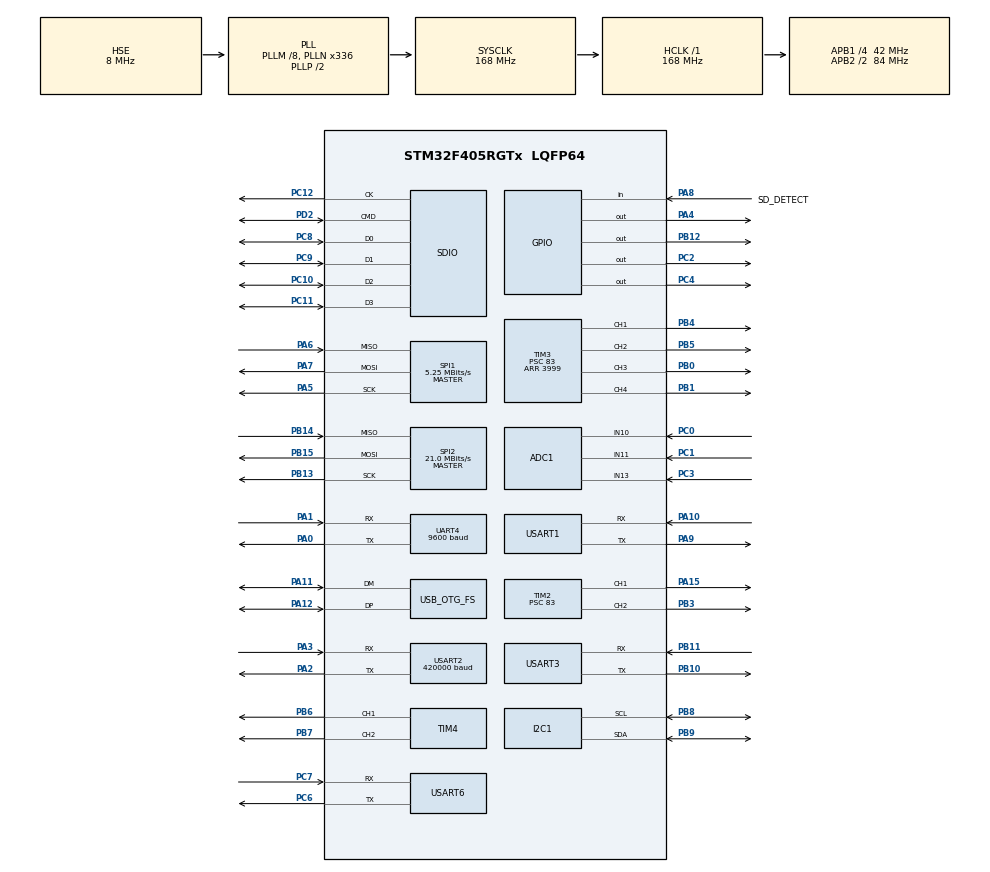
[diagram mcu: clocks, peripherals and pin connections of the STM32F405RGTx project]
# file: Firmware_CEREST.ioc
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ADC1.Channel-0\#ChannelRegularConversion=ADC_CHANNEL_10
ADC1.NbrOfConversionFlag=1
ADC1.Rank-0\#ChannelRegularConversion=1
ADC1.SamplingTime-0\#ChannelRegularConversion=ADC_SAMPLETIME_3CYCLES
ADC1.master=1
Dma.Request0=UART4_TX
Dma.Request1=USART2_RX
Dma.Request2=USART2_TX
Dma.Request3=USART6_RX
Dma.Request4=USART6_TX
Dma.UART4_TX.0.Direction=DMA_MEMORY_TO_PERIPH
Dma.UART4_TX.0.FIFOMode=DMA_FIFOMODE_DISABLE
Dma.UART4_TX.0.Instance=DMA1_Stream4
Dma.UART4_TX.0.MemDataAlignment=DMA_MDATAALIGN_BYTE
Dma.UART4_TX.0.MemInc=DMA_MINC_ENABLE
Dma.UART4_TX.0.Mode=DMA_NORMAL
Dma.UART4_TX.0.PeriphDataAlignment=DMA_PDATAALIGN_BYTE
Dma.UART4_TX.0.PeriphInc=DMA_PINC_DISABLE
Dma.UART4_TX.0.Priority=DMA_PRIORITY_LOW
Dma.USART2_RX.1.Direction=DMA_PERIPH_TO_MEMORY
Dma.USART2_RX.1.FIFOMode=DMA_FIFOMODE_DISABLE
Dma.USART2_RX.1.Instance=DMA1_Stream5
Dma.USART2_RX.1.MemDataAlignment=DMA_MDATAALIGN_BYTE
Dma.USART2_RX.1.MemInc=DMA_MINC_ENABLE
Dma.USART2_RX.1.Mode=DMA_CIRCULAR
Dma.USART2_RX.1.PeriphDataAlignment=DMA_PDATAALIGN_BYTE
Dma.USART2_RX.1.PeriphInc=DMA_PINC_DISABLE
Dma.USART2_RX.1.Priority=DMA_PRIORITY_VERY_HIGH
Dma.USART2_TX.2.Direction=DMA_MEMORY_TO_PERIPH
Dma.USART2_TX.2.FIFOMode=DMA_FIFOMODE_DISABLE
Dma.USART2_TX.2.Instance=DMA1_Stream6
Dma.USART2_TX.2.MemDataAlignment=DMA_MDATAALIGN_BYTE
Dma.USART2_TX.2.MemInc=DMA_MINC_ENABLE
Dma.USART2_TX.2.Mode=DMA_NORMAL
Dma.USART2_TX.2.PeriphDataAlignment=DMA_PDATAALIGN_BYTE
Dma.USART2_TX.2.PeriphInc=DMA_PINC_DISABLE
Dma.USART2_TX.2.Priority=DMA_PRIORITY_VERY_HIGH
Dma.USART6_RX.3.Direction=DMA_PERIPH_TO_MEMORY
Dma.USART6_RX.3.FIFOMode=DMA_FIFOMODE_DISABLE
Dma.USART6_RX.3.Instance=DMA2_Stream1
Dma.USART6_RX.3.MemDataAlignment=DMA_MDATAALIGN_BYTE
Dma.USART6_RX.3.MemInc=DMA_MINC_ENABLE
Dma.USART6_RX.3.Mode=DMA_CIRCULAR
Dma.USART6_RX.3.PeriphDataAlignment=DMA_PDATAALIGN_BYTE
Dma.USART6_RX.3.PeriphInc=DMA_PINC_DISABLE
Dma.USART6_RX.3.Priority=DMA_PRIORITY_VERY_HIGH
Dma.USART6_TX.4.Direction=DMA_MEMORY_TO_PERIPH
Dma.USART6_TX.4.FIFOMode=DMA_FIFOMODE_DISABLE
Dma.USART6_TX.4.Instance=DMA2_Stream6
Dma.USART6_TX.4.MemDataAlignment=DMA_MDATAALIGN_BYTE
Dma.USART6_TX.4.MemInc=DMA_MINC_ENABLE
Dma.USART6_TX.4.Mode=DMA_NORMAL
Dma.USART6_TX.4.PeriphDataAlignment=DMA_PDATAALIGN_BYTE
Dma.USART6_TX.4.PeriphInc=DMA_PINC_DISABLE
Dma.USART6_TX.4.Priority=DMA_PRIORITY_VERY_HIGH
FATFS._MAX_SS=4096
I2C1.I2C_Mode=I2C_Fast
Mcu.Family=STM32F4
Mcu.Name=STM32F405RGTx
Mcu.Package=LQFP64
NVIC.DMA1_Stream4_IRQn=true\:0\:0\:false\:false\:true\:false\:true\:true
NVIC.DMA1_Stream5_IRQn=true\:0\:0\:false\:false\:true\:false\:true\:true
NVIC.DMA1_Stream6_IRQn=true\:0\:0\:false\:false\:true\:false\:true\:true
NVIC.DMA2_Stream1_IRQn=true\:0\:0\:false\:false\:true\:false\:true\:true
NVIC.DMA2_Stream6_IRQn=true\:0\:0\:false\:false\:true\:false\:true\:true
NVIC.OTG_FS_IRQn=true\:0\:0\:false\:false\:true\:false\:true\:true
NVIC.PriorityGroup=NVIC_PRIORITYGROUP_4
NVIC.SDIO_IRQn=true\:0\:0\:false\:false\:true\:true\:true\:true
NVIC.UART4_IRQn=true\:0\:0\:false\:false\:true\:true\:true\:true
NVIC.USART2_IRQn=true\:0\:0\:false\:false\:true\:true\:true\:true
NVIC.USART6_IRQn=true\:0\:0\:false\:false\:true\:true\:true\:true
PA0-WKUP.Mode=Asynchronous
PA0-WKUP.Signal=UART4_TX
PA1.Mode=Asynchronous
PA1.Signal=UART4_RX
PA10.Mode=Asynchronous
PA10.Signal=USART1_RX
PA11.Mode=Device_Only
PA11.Signal=USB_OTG_FS_DM
PA12.Mode=Device_Only
PA12.Signal=USB_OTG_FS_DP
PA13.Mode=Serial_Wire
PA13.Signal=SYS_JTMS-SWDIO
PA14.Mode=Serial_Wire
PA14.Signal=SYS_JTCK-SWCLK
PA15.Signal=S_TIM2_CH1_ETR
PA2.Mode=Asynchronous
PA2.Signal=USART2_TX
PA3.Mode=Asynchronous
PA3.Signal=USART2_RX
PA4.Signal=GPIO_Output
PA5.Mode=Full_Duplex_Master
PA5.Signal=SPI1_SCK
PA6.Mode=Full_Duplex_Master
PA6.Signal=SPI1_MISO
PA7.Mode=Full_Duplex_Master
PA7.Signal=SPI1_MOSI
PA8.GPIO_Label=SD_DETECT
PA8.GPIO_PuPd=GPIO_PULLUP
PA8.Signal=GPIO_Input
PA9.Mode=Asynchronous
PA9.Signal=USART1_TX
PB0.Signal=S_TIM3_CH3
PB1.Signal=S_TIM3_CH4
PB10.Mode=Asynchronous
PB10.Signal=USART3_TX
PB11.Mode=Asynchronous
PB11.Signal=USART3_RX
PB12.Signal=GPIO_Output
PB13.Mode=Full_Duplex_Master
PB13.Signal=SPI2_SCK
PB14.Mode=Full_Duplex_Master
PB14.Signal=SPI2_MISO
PB15.Mode=Full_Duplex_Master
PB15.Signal=SPI2_MOSI
PB3.Signal=S_TIM2_CH2
PB4.Signal=S_TIM3_CH1
PB5.Signal=S_TIM3_CH2
PB6.Signal=S_TIM4_CH1
PB7.Signal=S_TIM4_CH2
PB8.Mode=I2C
PB8.Signal=I2C1_SCL
PB9.Mode=I2C
PB9.Signal=I2C1_SDA
PC0.Signal=ADCx_IN10
PC1.Signal=ADCx_IN11
PC10.GPIO_PuPd=GPIO_PULLUP
PC10.Mode=SD_4_bits_Wide_bus
PC10.Signal=SDIO_D2
PC11.GPIO_PuPd=GPIO_PULLUP
PC11.Mode=SD_4_bits_Wide_bus
PC11.Signal=SDIO_D3
PC12.Mode=SD_4_bits_Wide_bus
PC12.Signal=SDIO_CK
PC2.GPIO_PuPd=GPIO_NOPULL
PC2.PinState=GPIO_PIN_SET
PC2.Signal=GPIO_Output
PC3.Signal=ADCx_IN13
PC4.GPIO_PuPd=GPIO_NOPULL
PC4.PinState=GPIO_PIN_RESET
PC4.Signal=GPIO_Output
PC6.Mode=Asynchronous
PC6.Signal=USART6_TX
PC7.Mode=Asynchronous
PC7.Signal=USART6_RX
PC8.GPIO_PuPd=GPIO_PULLUP
PC8.Mode=SD_4_bits_Wide_bus
PC8.Signal=SDIO_D0
PC9.GPIO_PuPd=GPIO_PULLUP
PC9.Mode=SD_4_bits_Wide_bus
PC9.Signal=SDIO_D1
PD2.GPIO_PuPd=GPIO_PULLUP
PD2.Mode=SD_4_bits_Wide_bus
PD2.Signal=SDIO_CMD
PH0-OSC_IN.Mode=HSE-External-Oscillator
PH0-OSC_IN.Signal=RCC_OSC_IN
PH1-OSC_OUT.Mode=HSE-External-Oscillator
PH1-OSC_OUT.Signal=RCC_OSC_OUT
ProjectManager.HeapSize=0x200
ProjectManager.StackSize=0x400
ProjectManager.TargetToolchain=CMake
RCC.48MHZClocksFreq_Value=48000000
RCC.AHBFreq_Value=168000000
RCC.APB1CLKDivider=RCC_HCLK_DIV4
RCC.APB1Freq_Value=42000000
RCC.APB1TimFreq_Value=84000000
RCC.APB2CLKDivider=RCC_HCLK_DIV2
RCC.APB2Freq_Value=84000000
RCC.APB2TimFreq_Value=168000000
RCC.CortexFreq_Value=168000000
RCC.HCLKFreq_Value=168000000
RCC.HSE_VALUE=8000000
RCC.HSI_VALUE=16000000
RCC.LSE_VALUE=32768
RCC.PLLM=8
RCC.PLLN=336
RCC.PLLQ=7
RCC.SYSCLKFreq_VALUE=168000000
RCC.SYSCLKSource=RCC_SYSCLKSOURCE_PLLCLK
RCC.VCOOutputFreq_Value=336000000
SDIO.ClockDiv=8
SH.ADCx_IN10.0=ADC1_IN10,IN10
SH.ADCx_IN11.0=ADC1_IN11,IN11
SH.ADCx_IN13.0=ADC1_IN13,IN13
SH.S_TIM2_CH1_ETR.0=TIM2_CH1,PWM Generation1 CH1
SH.S_TIM2_CH2.0=TIM2_CH2,PWM Generation2 CH2
SH.S_TIM3_CH1.0=TIM3_CH1,PWM Generation1 CH1
SH.S_TIM3_CH2.0=TIM3_CH2,PWM Generation2 CH2
SH.S_TIM3_CH3.0=TIM3_CH3,PWM Generation3 CH3
SH.S_TIM3_CH4.0=TIM3_CH4,PWM Generation4 CH4
SH.S_TIM4_CH1.0=TIM4_CH1,PWM Generation1 CH1
SH.S_TIM4_CH2.0=TIM4_CH2,PWM Generation2 CH2
SPI1.BaudRatePrescaler=SPI_BAUDRATEPRESCALER_16
SPI1.CalculateBaudRate=5.25 MBits/s
SPI1.Direction=SPI_DIRECTION_2LINES
SPI1.Mode=SPI_MODE_MASTER
SPI1.VirtualType=VM_MASTER
SPI2.BaudRatePrescaler=SPI_BAUDRATEPRESCALER_2
SPI2.CalculateBaudRate=21.0 MBits/s
SPI2.Direction=SPI_DIRECTION_2LINES
SPI2.Mode=SPI_MODE_MASTER
SPI2.VirtualType=VM_MASTER
TIM2.Channel-PWM\ Generation1\ CH1=TIM_CHANNEL_1
TIM2.Channel-PWM\ Generation2\ CH2=TIM_CHANNEL_2
TIM2.Period=19999
TIM2.Prescaler=83
TIM3.Channel-PWM\ Generation1\ CH1=TIM_CHANNEL_1
TIM3.Channel-PWM\ Generation2\ CH2=TIM_CHANNEL_2
TIM3.Channel-PWM\ Generation3\ CH3=TIM_CHANNEL_3
TIM3.Channel-PWM\ Generation4\ CH4=TIM_CHANNEL_4
TIM3.OC1Preload_PWM=ENABLE
TIM3.OC2Preload_PWM=ENABLE
TIM3.OCMode_PWM-PWM\ Generation1\ CH1=TIM_OCMODE_PWM1
TIM3.OCMode_PWM-PWM\ Generation2\ CH2=TIM_OCMODE_PWM1
TIM3.OCPolarity_1=TIM_OCPOLARITY_HIGH
TIM3.OCPolarity_2=TIM_OCPOLARITY_HIGH
TIM3.Period=3999
TIM3.Prescaler=83
TIM4.Channel-PWM\ Generation1\ CH1=TIM_CHANNEL_1
TIM4.Channel-PWM\ Generation2\ CH2=TIM_CHANNEL_2
TIM5.Prescaler=83
UART4.BaudRate=9600
UART4.VirtualMode=Asynchronous
USART1.VirtualMode=VM_ASYNC
USART2.BaudRate=420000
USART2.VirtualMode=VM_ASYNC
USART3.VirtualMode=VM_ASYNC
USART6.VirtualMode=VM_ASYNC
USB_DEVICE.CLASS_NAME_FS=CDC
USB_DEVICE.VirtualMode-CDC_FS=Cdc
USB_DEVICE.VirtualModeFS=Cdc_FS
USB_OTG_FS.VirtualMode=Device_Only
VP_FATFS_VS_SDIO.Mode=SDIO
VP_TIM2_VS_ClockSourceINT.Mode=Internal
VP_TIM3_VS_ClockSourceINT.Mode=Internal
VP_TIM5_VS_ClockSourceINT.Mode=Internal
VP_USB_DEVICE_VS_USB_DEVICE_CDC_FS.Mode=CDC_FS
board=custom

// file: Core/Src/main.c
/* USER CODE BEGIN Header */
/**
  ******************************************************************************
  * @file           : main.c
  * @brief          : Main program body
  ******************************************************************************
  * @attention
  *
  * Copyright (c) 2026 STMicroelectronics.
  * All rights reserved.
  *
  * This software is licensed under terms that can be found in the LICENSE file
  * in the root directory of this software component.
  * If no LICENSE file comes with this software, it is provided AS-IS.
  *
  ******************************************************************************
  */
/* USER CODE END Header */
#include "main.h"
#include "fatfs.h"
#include "usb_device.h"

/* USER CODE BEGIN Includes */
#include "puente.h"
/* USER CODE END Includes */

ADC_HandleTypeDef hadc1;

I2C_HandleTypeDef hi2c1;

SD_HandleTypeDef hsd;

SPI_HandleTypeDef hspi1;
SPI_HandleTypeDef hspi2;

TIM_HandleTypeDef htim2;
TIM_HandleTypeDef htim3;
TIM_HandleTypeDef htim4;
TIM_HandleTypeDef htim5;

UART_HandleTypeDef huart4;
UART_HandleTypeDef huart1;
UART_HandleTypeDef huart2;
UART_HandleTypeDef huart3;
UART_HandleTypeDef huart6;
DMA_HandleTypeDef hdma_uart4_tx;
DMA_HandleTypeDef hdma_usart2_rx;
DMA_HandleTypeDef hdma_usart2_tx;
DMA_HandleTypeDef hdma_usart6_rx;
DMA_HandleTypeDef hdma_usart6_tx;

void SystemClock_Config(void);
static void MX_GPIO_Init(void);
static void MX_DMA_Init(void);
static void MX_SPI2_Init(void);
static void MX_I2C1_Init(void);
static void MX_UART4_Init(void);
static void MX_USART6_UART_Init(void);
static void MX_USART2_UART_Init(void);
static void MX_TIM3_Init(void);
static void MX_TIM4_Init(void);
static void MX_TIM2_Init(void);
static void MX_SPI1_Init(void);
static void MX_ADC1_Init(void);
static void MX_TIM5_Init(void);
static void MX_SDIO_SD_Init(void);
static void MX_USART1_UART_Init(void);
static void MX_USART3_UART_Init(void);

int main(void)
{

  /* MCU Configuration--------------------------------------------------------*/

  /* Reset of all peripherals, Initializes the Flash interface and the Systick. */
  HAL_Init();

  /* Configure the system clock */
  SystemClock_Config();

  /* Initialize all configured peripherals */
  MX_GPIO_Init();
  MX_DMA_Init();
  MX_SPI2_Init();
  MX_USB_DEVICE_Init();
  MX_I2C1_Init();
  MX_UART4_Init();
  MX_USART6_UART_Init();
  MX_USART2_UART_Init();
  MX_TIM3_Init();
  MX_TIM4_Init();
  MX_TIM2_Init();
  MX_SPI1_Init();
  MX_ADC1_Init();
  MX_TIM5_Init();
  MX_SDIO_SD_Init();
  MX_USART1_UART_Init();
  MX_USART3_UART_Init();
  MX_FATFS_Init();
  /* USER CODE BEGIN 2 */
  HAL_TIM_Base_Start(&htim5);
  App_Init();
  /* USER CODE END 2 */

  /* Infinite loop */
  while (1)
  {

    /* USER CODE BEGIN 3 */
    App_Loop();
  }
  /* USER CODE END 3 */
}

void SystemClock_Config(void)
{
  RCC_OscInitTypeDef RCC_OscInitStruct = {0};
  RCC_ClkInitTypeDef RCC_ClkInitStruct = {0};

  /** Configure the main internal regulator output voltage
  */
  __HAL_RCC_PWR_CLK_ENABLE();
  __HAL_PWR_VOLTAGESCALING_CONFIG(PWR_REGULATOR_VOLTAGE_SCALE1);

  /** Initializes the RCC Oscillators according to the specified parameters
  * in the RCC_OscInitTypeDef structure.
  */
  RCC_OscInitStruct.OscillatorType = RCC_OSCILLATORTYPE_HSE;
  RCC_OscInitStruct.HSEState = RCC_HSE_ON;
  RCC_OscInitStruct.PLL.PLLState = RCC_PLL_ON;
  RCC_OscInitStruct.PLL.PLLSource = RCC_PLLSOURCE_HSE;
  RCC_OscInitStruct.PLL.PLLM = 8;
  RCC_OscInitStruct.PLL.PLLN = 336;
  RCC_OscInitStruct.PLL.PLLP = RCC_PLLP_DIV2;
  RCC_OscInitStruct.PLL.PLLQ = 7;
  if (HAL_RCC_OscConfig(&RCC_OscInitStruct) != HAL_OK)
  {
    Error_Handler();
  }

  /** Initializes the CPU, AHB and APB buses clocks
  */
  RCC_ClkInitStruct.ClockType = RCC_CLOCKTYPE_HCLK|RCC_CLOCKTYPE_SYSCLK
                              |RCC_CLOCKTYPE_PCLK1|RCC_CLOCKTYPE_PCLK2;
  RCC_ClkInitStruct.SYSCLKSource = RCC_SYSCLKSOURCE_PLLCLK;
  RCC_ClkInitStruct.AHBCLKDivider = RCC_SYSCLK_DIV1;
  RCC_ClkInitStruct.APB1CLKDivider = RCC_HCLK_DIV4;
  RCC_ClkInitStruct.APB2CLKDivider = RCC_HCLK_DIV2;

  if (HAL_RCC_ClockConfig(&RCC_ClkInitStruct, FLASH_LATENCY_5) != HAL_OK)
  {
    Error_Handler();
  }
}

static void MX_ADC1_Init(void)
{

  ADC_ChannelConfTypeDef sConfig = {0};

  /** Configure the global features of the ADC (Clock, Resolution, Data Alignment and number of conversion)
  */
  hadc1.Instance = ADC1;
  hadc1.Init.ClockPrescaler = ADC_CLOCK_SYNC_PCLK_DIV4;
  hadc1.Init.Resolution = ADC_RESOLUTION_12B;
  hadc1.Init.ScanConvMode = DISABLE;
  hadc1.Init.ContinuousConvMode = DISABLE;
  hadc1.Init.DiscontinuousConvMode = DISABLE;
  hadc1.Init.ExternalTrigConvEdge = ADC_EXTERNALTRIGCONVEDGE_NONE;
  hadc1.Init.ExternalTrigConv = ADC_SOFTWARE_START;
  hadc1.Init.DataAlign = ADC_DATAALIGN_RIGHT;
  hadc1.Init.NbrOfConversion = 1;
  hadc1.Init.DMAContinuousRequests = DISABLE;
  hadc1.Init.EOCSelection = ADC_EOC_SINGLE_CONV;
  if (HAL_ADC_Init(&hadc1) != HAL_OK)
  {
    Error_Handler();
  }

  /** Configure for the selected ADC regular channel its corresponding rank in the sequencer and its sample time.
  */
  sConfig.Channel = ADC_CHANNEL_10;
  sConfig.Rank = 1;
  sConfig.SamplingTime = ADC_SAMPLETIME_3CYCLES;
  if (HAL_ADC_ConfigChannel(&hadc1, &sConfig) != HAL_OK)
  {
    Error_Handler();
  }

}

static void MX_I2C1_Init(void)
{

  hi2c1.Instance = I2C1;
  hi2c1.Init.ClockSpeed = 400000;
  hi2c1.Init.DutyCycle = I2C_DUTYCYCLE_2;
  hi2c1.Init.OwnAddress1 = 0;
  hi2c1.Init.AddressingMode = I2C_ADDRESSINGMODE_7BIT;
  hi2c1.Init.DualAddressMode = I2C_DUALADDRESS_DISABLE;
  hi2c1.Init.OwnAddress2 = 0;
  hi2c1.Init.GeneralCallMode = I2C_GENERALCALL_DISABLE;
  hi2c1.Init.NoStretchMode = I2C_NOSTRETCH_DISABLE;
  if (HAL_I2C_Init(&hi2c1) != HAL_OK)
  {
    Error_Handler();
  }

}

static void MX_SDIO_SD_Init(void)
{

  hsd.Instance = SDIO;
  hsd.Init.ClockEdge = SDIO_CLOCK_EDGE_RISING;
  hsd.Init.ClockBypass = SDIO_CLOCK_BYPASS_DISABLE;
  hsd.Init.ClockPowerSave = SDIO_CLOCK_POWER_SAVE_DISABLE;
  hsd.Init.BusWide = SDIO_BUS_WIDE_1B;
  hsd.Init.HardwareFlowControl = SDIO_HARDWARE_FLOW_CONTROL_DISABLE;
  hsd.Init.ClockDiv = 8;

}

static void MX_SPI1_Init(void)
{

  /* SPI1 parameter configuration*/
  hspi1.Instance = SPI1;
  hspi1.Init.Mode = SPI_MODE_MASTER;
  hspi1.Init.Direction = SPI_DIRECTION_2LINES;
  hspi1.Init.DataSize = SPI_DATASIZE_8BIT;
  hspi1.Init.CLKPolarity = SPI_POLARITY_LOW;
  hspi1.Init.CLKPhase = SPI_PHASE_1EDGE;
  hspi1.Init.NSS = SPI_NSS_SOFT;
  hspi1.Init.BaudRatePrescaler = SPI_BAUDRATEPRESCALER_16;
  hspi1.Init.FirstBit = SPI_FIRSTBIT_MSB;
  hspi1.Init.TIMode = SPI_TIMODE_DISABLE;
  hspi1.Init.CRCCalculation = SPI_CRCCALCULATION_DISABLE;
  hspi1.Init.CRCPolynomial = 10;
  if (HAL_SPI_Init(&hspi1) != HAL_OK)
  {
    Error_Handler();
  }

}

static void MX_SPI2_Init(void)
{

  /* SPI2 parameter configuration*/
  hspi2.Instance = SPI2;
  hspi2.Init.Mode = SPI_MODE_MASTER;
  hspi2.Init.Direction = SPI_DIRECTION_2LINES;
  hspi2.Init.DataSize = SPI_DATASIZE_8BIT;
  hspi2.Init.CLKPolarity = SPI_POLARITY_LOW;
  hspi2.Init.CLKPhase = SPI_PHASE_1EDGE;
  hspi2.Init.NSS = SPI_NSS_SOFT;
  hspi2.Init.BaudRatePrescaler = SPI_BAUDRATEPRESCALER_2;
  hspi2.Init.FirstBit = SPI_FIRSTBIT_MSB;
  hspi2.Init.TIMode = SPI_TIMODE_DISABLE;
  hspi2.Init.CRCCalculation = SPI_CRCCALCULATION_DISABLE;
  hspi2.Init.CRCPolynomial = 10;
  if (HAL_SPI_Init(&hspi2) != HAL_OK)
  {
    Error_Handler();
  }

}

static void MX_TIM2_Init(void)
{

  TIM_ClockConfigTypeDef sClockSourceConfig = {0};
  TIM_MasterConfigTypeDef sMasterConfig = {0};
  TIM_OC_InitTypeDef sConfigOC = {0};

  htim2.Instance = TIM2;
  htim2.Init.Prescaler = 83;
  htim2.Init.CounterMode = TIM_COUNTERMODE_UP;
  htim2.Init.Period = 19999;
  htim2.Init.ClockDivision = TIM_CLOCKDIVISION_DIV1;
  htim2.Init.AutoReloadPreload = TIM_AUTORELOAD_PRELOAD_DISABLE;
  if (HAL_TIM_Base_Init(&htim2) != HAL_OK)
  {
    Error_Handler();
  }
  sClockSourceConfig.ClockSource = TIM_CLOCKSOURCE_INTERNAL;
  if (HAL_TIM_ConfigClockSource(&htim2, &sClockSourceConfig) != HAL_OK)
  {
    Error_Handler();
  }
  if (HAL_TIM_PWM_Init(&htim2) != HAL_OK)
  {
    Error_Handler();
  }
  sMasterConfig.MasterOutputTrigger = TIM_TRGO_RESET;
  sMasterConfig.MasterSlaveMode = TIM_MASTERSLAVEMODE_DISABLE;
  if (HAL_TIMEx_MasterConfigSynchronization(&htim2, &sMasterConfig) != HAL_OK)
  {
    Error_Handler();
  }
  sConfigOC.OCMode = TIM_OCMODE_PWM1;
  sConfigOC.Pulse = 0;
  sConfigOC.OCPolarity = TIM_OCPOLARITY_HIGH;
  sConfigOC.OCFastMode = TIM_OCFAST_DISABLE;
  if (HAL_TIM_PWM_ConfigChannel(&htim2, &sConfigOC, TIM_CHANNEL_1) != HAL_OK)
  {
    Error_Handler();
  }
  if (HAL_TIM_PWM_ConfigChannel(&htim2, &sConfigOC, TIM_CHANNEL_2) != HAL_OK)
  {
    Error_Handler();
  }
  HAL_TIM_MspPostInit(&htim2);

}

static void MX_TIM3_Init(void)
{

  TIM_ClockConfigTypeDef sClockSourceConfig = {0};
  TIM_MasterConfigTypeDef sMasterConfig = {0};
  TIM_OC_InitTypeDef sConfigOC = {0};

  htim3.Instance = TIM3;
  htim3.Init.Prescaler = 83;
  htim3.Init.CounterMode = TIM_COUNTERMODE_UP;
  htim3.Init.Period = 3999;
  htim3.Init.ClockDivision = TIM_CLOCKDIVISION_DIV1;
  htim3.Init.AutoReloadPreload = TIM_AUTORELOAD_PRELOAD_DISABLE;
  if (HAL_TIM_Base_Init(&htim3) != HAL_OK)
  {
    Error_Handler();
  }
  sClockSourceConfig.ClockSource = TIM_CLOCKSOURCE_INTERNAL;
  if (HAL_TIM_ConfigClockSource(&htim3, &sClockSourceConfig) != HAL_OK)
  {
    Error_Handler();
  }
  if (HAL_TIM_PWM_Init(&htim3) != HAL_OK)
  {
    Error_Handler();
  }
  sMasterConfig.MasterOutputTrigger = TIM_TRGO_RESET;
  sMasterConfig.MasterSlaveMode = TIM_MASTERSLAVEMODE_DISABLE;
  if (HAL_TIMEx_MasterConfigSynchronization(&htim3, &sMasterConfig) != HAL_OK)
  {
    Error_Handler();
  }
  sConfigOC.OCMode = TIM_OCMODE_PWM1;
  sConfigOC.Pulse = 0;
  sConfigOC.OCPolarity = TIM_OCPOLARITY_HIGH;
  sConfigOC.OCFastMode = TIM_OCFAST_DISABLE;
  if (HAL_TIM_PWM_ConfigChannel(&htim3, &sConfigOC, TIM_CHANNEL_1) != HAL_OK)
  {
    Error_Handler();
  }
  if (HAL_TIM_PWM_ConfigChannel(&htim3, &sConfigOC, TIM_CHANNEL_2) != HAL_OK)
  {
    Error_Handler();
  }
  if (HAL_TIM_PWM_ConfigChannel(&htim3, &sConfigOC, TIM_CHANNEL_3) != HAL_OK)
  {
    Error_Handler();
  }
  if (HAL_TIM_PWM_ConfigChannel(&htim3, &sConfigOC, TIM_CHANNEL_4) != HAL_OK)
  {
    Error_Handler();
  }
  HAL_TIM_MspPostInit(&htim3);

}

static void MX_TIM4_Init(void)
{

  TIM_MasterConfigTypeDef sMasterConfig = {0};
  TIM_OC_InitTypeDef sConfigOC = {0};

  htim4.Instance = TIM4;
  htim4.Init.Prescaler = 0;
  htim4.Init.CounterMode = TIM_COUNTERMODE_UP;
  htim4.Init.Period = 65535;
  htim4.Init.ClockDivision = TIM_CLOCKDIVISION_DIV1;
  htim4.Init.AutoReloadPreload = TIM_AUTORELOAD_PRELOAD_DISABLE;
  if (HAL_TIM_PWM_Init(&htim4) != HAL_OK)
  {
    Error_Handler();
  }
  sMasterConfig.MasterOutputTrigger = TIM_TRGO_RESET;
  sMasterConfig.MasterSlaveMode = TIM_MASTERSLAVEMODE_DISABLE;
  if (HAL_TIMEx_MasterConfigSynchronization(&htim4, &sMasterConfig) != HAL_OK)
  {
    Error_Handler();
  }
  sConfigOC.OCMode = TIM_OCMODE_PWM1;
  sConfigOC.Pulse = 0;
  sConfigOC.OCPolarity = TIM_OCPOLARITY_HIGH;
  sConfigOC.OCFastMode = TIM_OCFAST_DISABLE;
  if (HAL_TIM_PWM_ConfigChannel(&htim4, &sConfigOC, TIM_CHANNEL_1) != HAL_OK)
  {
    Error_Handler();
  }
  if (HAL_TIM_PWM_ConfigChannel(&htim4, &sConfigOC, TIM_CHANNEL_2) != HAL_OK)
  {
    Error_Handler();
  }
  HAL_TIM_MspPostInit(&htim4);

}

static void MX_TIM5_Init(void)
{

  TIM_ClockConfigTypeDef sClockSourceConfig = {0};
  TIM_MasterConfigTypeDef sMasterConfig = {0};

  htim5.Instance = TIM5;
  htim5.Init.Prescaler = 83;
  htim5.Init.CounterMode = TIM_COUNTERMODE_UP;
  htim5.Init.Period = 4294967295;
  htim5.Init.ClockDivision = TIM_CLOCKDIVISION_DIV1;
  htim5.Init.AutoReloadPreload = TIM_AUTORELOAD_PRELOAD_DISABLE;
  if (HAL_TIM_Base_Init(&htim5) != HAL_OK)
  {
    Error_Handler();
  }
  sClockSourceConfig.ClockSource = TIM_CLOCKSOURCE_INTERNAL;
  if (HAL_TIM_ConfigClockSource(&htim5, &sClockSourceConfig) != HAL_OK)
  {
    Error_Handler();
  }
  sMasterConfig.MasterOutputTrigger = TIM_TRGO_RESET;
  sMasterConfig.MasterSlaveMode = TIM_MASTERSLAVEMODE_DISABLE;
  if (HAL_TIMEx_MasterConfigSynchronization(&htim5, &sMasterConfig) != HAL_OK)
  {
    Error_Handler();
  }

}

static void MX_UART4_Init(void)
{

  huart4.Instance = UART4;
  huart4.Init.BaudRate = 9600;
  huart4.Init.WordLength = UART_WORDLENGTH_8B;
  huart4.Init.StopBits = UART_STOPBITS_1;
  huart4.Init.Parity = UART_PARITY_NONE;
  huart4.Init.Mode = UART_MODE_TX_RX;
  huart4.Init.HwFlowCtl = UART_HWCONTROL_NONE;
  huart4.Init.OverSampling = UART_OVERSAMPLING_16;
  if (HAL_UART_Init(&huart4) != HAL_OK)
  {
    Error_Handler();
  }

}

static void MX_USART1_UART_Init(void)
{

  huart1.Instance = USART1;
  huart1.Init.BaudRate = 115200;
  huart1.Init.WordLength = UART_WORDLENGTH_8B;
  huart1.Init.StopBits = UART_STOPBITS_1;
  huart1.Init.Parity = UART_PARITY_NONE;
  huart1.Init.Mode = UART_MODE_TX_RX;
  huart1.Init.HwFlowCtl = UART_HWCONTROL_NONE;
  huart1.Init.OverSampling = UART_OVERSAMPLING_16;
  if (HAL_UART_Init(&huart1) != HAL_OK)
  {
    Error_Handler();
  }

}

static void MX_USART2_UART_Init(void)
{

  huart2.Instance = USART2;
  huart2.Init.BaudRate = 420000;
  huart2.Init.WordLength = UART_WORDLENGTH_8B;
  huart2.Init.StopBits = UART_STOPBITS_1;
  huart2.Init.Parity = UART_PARITY_NONE;
  huart2.Init.Mode = UART_MODE_TX_RX;
  huart2.Init.HwFlowCtl = UART_HWCONTROL_NONE;
  huart2.Init.OverSampling = UART_OVERSAMPLING_16;
  if (HAL_UART_Init(&huart2) != HAL_OK)
  {
    Error_Handler();
  }

}

static void MX_USART3_UART_Init(void)
{

  huart3.Instance = USART3;
  huart3.Init.BaudRate = 115200;
  huart3.Init.WordLength = UART_WORDLENGTH_8B;
  huart3.Init.StopBits = UART_STOPBITS_1;
  huart3.Init.Parity = UART_PARITY_NONE;
  huart3.Init.Mode = UART_MODE_TX_RX;
  huart3.Init.HwFlowCtl = UART_HWCONTROL_NONE;
  huart3.Init.OverSampling = UART_OVERSAMPLING_16;
  if (HAL_UART_Init(&huart3) != HAL_OK)
  {
    Error_Handler();
  }

}

static void MX_USART6_UART_Init(void)
{

  huart6.Instance = USART6;
  huart6.Init.BaudRate = 115200;
  huart6.Init.WordLength = UART_WORDLENGTH_8B;
  huart6.Init.StopBits = UART_STOPBITS_1;
  huart6.Init.Parity = UART_PARITY_NONE;
  huart6.Init.Mode = UART_MODE_TX_RX;
  huart6.Init.HwFlowCtl = UART_HWCONTROL_NONE;
  huart6.Init.OverSampling = UART_OVERSAMPLING_16;
  if (HAL_UART_Init(&huart6) != HAL_OK)
  {
    Error_Handler();
  }

}

static void MX_DMA_Init(void)
{

  /* DMA controller clock enable */
  __HAL_RCC_DMA1_CLK_ENABLE();
  __HAL_RCC_DMA2_CLK_ENABLE();

  /* DMA interrupt init */
  /* DMA1_Stream4_IRQn interrupt configuration */
  HAL_NVIC_SetPriority(DMA1_Stream4_IRQn, 0, 0);
  HAL_NVIC_EnableIRQ(DMA1_Stream4_IRQn);
  /* DMA1_Stream5_IRQn interrupt configuration */
  HAL_NVIC_SetPriority(DMA1_Stream5_IRQn, 0, 0);
  HAL_NVIC_EnableIRQ(DMA1_Stream5_IRQn);
  /* DMA1_Stream6_IRQn interrupt configuration */
  HAL_NVIC_SetPriority(DMA1_Stream6_IRQn, 0, 0);
  HAL_NVIC_EnableIRQ(DMA1_Stream6_IRQn);
  /* DMA2_Stream1_IRQn interrupt configuration */
  HAL_NVIC_SetPriority(DMA2_Stream1_IRQn, 0, 0);
  HAL_NVIC_EnableIRQ(DMA2_Stream1_IRQn);
  /* DMA2_Stream6_IRQn interrupt configuration */
  HAL_NVIC_SetPriority(DMA2_Stream6_IRQn, 0, 0);
  HAL_NVIC_EnableIRQ(DMA2_Stream6_IRQn);

}

static void MX_GPIO_Init(void)
{
  GPIO_InitTypeDef GPIO_InitStruct = {0};

  /* GPIO Ports Clock Enable */
  __HAL_RCC_GPIOH_CLK_ENABLE();
  __HAL_RCC_GPIOC_CLK_ENABLE();
  __HAL_RCC_GPIOA_CLK_ENABLE();
  __HAL_RCC_GPIOB_CLK_ENABLE();
  __HAL_RCC_GPIOD_CLK_ENABLE();

  /*Configure GPIO pin Output Level */
  HAL_GPIO_WritePin(GPIOC, GPIO_PIN_2, GPIO_PIN_SET);

  /*Configure GPIO pin Output Level */
  HAL_GPIO_WritePin(GPIOA, GPIO_PIN_4, GPIO_PIN_RESET);

  /*Configure GPIO pin Output Level */
  HAL_GPIO_WritePin(GPIOC, GPIO_PIN_4, GPIO_PIN_RESET);

  /*Configure GPIO pin Output Level */
  HAL_GPIO_WritePin(GPIOB, GPIO_PIN_12, GPIO_PIN_RESET);

  /*Configure GPIO pins : PC2 PC4 */
  GPIO_InitStruct.Pin = GPIO_PIN_2|GPIO_PIN_4;
  GPIO_InitStruct.Mode = GPIO_MODE_OUTPUT_PP;
  GPIO_InitStruct.Pull = GPIO_NOPULL;
  GPIO_InitStruct.Speed = GPIO_SPEED_FREQ_LOW;
  HAL_GPIO_Init(GPIOC, &GPIO_InitStruct);

  /*Configure GPIO pin : PA4 */
  GPIO_InitStruct.Pin = GPIO_PIN_4;
  GPIO_InitStruct.Mode = GPIO_MODE_OUTPUT_PP;
  GPIO_InitStruct.Pull = GPIO_NOPULL;
  GPIO_InitStruct.Speed = GPIO_SPEED_FREQ_LOW;
  HAL_GPIO_Init(GPIOA, &GPIO_InitStruct);

  /*Configure GPIO pin : PB12 */
  GPIO_InitStruct.Pin = GPIO_PIN_12;
  GPIO_InitStruct.Mode = GPIO_MODE_OUTPUT_PP;
  GPIO_InitStruct.Pull = GPIO_NOPULL;
  GPIO_InitStruct.Speed = GPIO_SPEED_FREQ_LOW;
  HAL_GPIO_Init(GPIOB, &GPIO_InitStruct);

  /*Configure GPIO pin : SD_DETECT_Pin */
  GPIO_InitStruct.Pin = SD_DETECT_Pin;
  GPIO_InitStruct.Mode = GPIO_MODE_INPUT;
  GPIO_InitStruct.Pull = GPIO_PULLUP;
  HAL_GPIO_Init(SD_DETECT_GPIO_Port, &GPIO_InitStruct);

}

void Error_Handler(void)
{
  __disable_irq();
  while (1)
  {
  }
}
